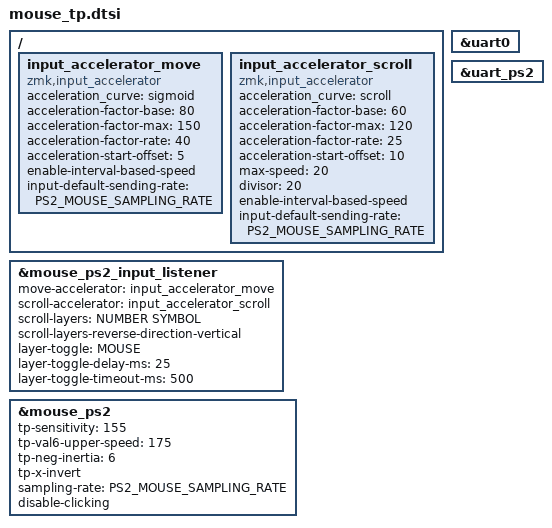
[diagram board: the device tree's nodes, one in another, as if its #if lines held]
#ifdef HAS_MOUSE_TP

#include <dt-bindings/zmk/mouse.h>
#include <dt-bindings/zmk/mouse_settings.h>
#include <behaviors/mouse_keys.dtsi>
#include <behaviors/mouse_setting.dtsi>
//#include <input/processors.dtsi>
//#include <dt-bindings/zmk/input_transform.h>
//#include <zephyr/dt-bindings/input/input-event-codes.h>

/*
* Key Behaviors to adjust settings
*/

// Sensitivity
#define U_MSS_TP_S_I &mms MS_TP_SENSITIVITY_INCR
#define U_MSS_TP_S_D &mms MS_TP_SENSITIVITY_DECR

// Max acceleration
#define U_MSS_TP_V6_I &mms MS_TP_VALUE6_INCR
#define U_MSS_TP_V6_D &mms MS_TP_VALUE6_DECR

// Negative intertia
#define U_MSS_TP_NI_I &mms MS_TP_NEG_INERTIA_INCR
#define U_MSS_TP_NI_D &mms MS_TP_NEG_INERTIA_DECR

#define U_MSS_RESET   &mms MS_RESET

#define U_MSS_LOG     &mms MS_LOG


#ifdef MOUSE_PS2_DT_PRESENT

#define PS2_MOUSE_SAMPLING_RATE 100

/*
* Input Listener Config
*/
/ {
    input_accelerator_move: input_accelerator_move {
        status = "okay";
        compatible = "zmk,input_accelerator";

        acceleration_curve = "sigmoid";
        acceleration-factor-base = <80>;
        acceleration-factor-max = <150>;
        acceleration-factor-rate = <40>;
        acceleration-start-offset = <5>;

        enable-interval-based-speed;
        input-default-sending-rate = <PS2_MOUSE_SAMPLING_RATE>;
    };
    input_accelerator_scroll: input_accelerator_scroll {
        status = "okay";
        compatible = "zmk,input_accelerator";

        acceleration_curve = "scroll";
        acceleration-factor-base = <60>;
        acceleration-factor-max = <120>;
        acceleration-factor-rate = <25>;
        acceleration-start-offset = <10>;
        max-speed = <20>;
        divisor = <20>;

        enable-interval-based-speed;
        input-default-sending-rate = <PS2_MOUSE_SAMPLING_RATE>;
    };
};

&mouse_ps2_input_listener { 
    move-accelerator = <&input_accelerator_move>;
    scroll-accelerator = <&input_accelerator_scroll>;

    scroll-layers = <NUMBER SYMBOL>; 
    scroll-layers-reverse-direction-vertical; 

    layer-toggle = <MOUSE>; 
    layer-toggle-delay-ms = <25>; 
    layer-toggle-timeout-ms = <500>; 
};

//&trackpoint_listener { 
//    input-processors = <&zip_temp_layer MOUSE 500>;
//};

/*
* Mouse Driver Settings
*/

&mouse_ps2 {
    // How sensitive the TP is (Default: 128)
    tp-sensitivity = <155>;
    // The maximum mouse movement speed the TP will accelarate to
    // (Default: 97)
    tp-val6-upper-speed = <175>;
    // Negative Inertia (Default: 6)
    // Makes the TP feel more responsive and "overshoot" less.
    tp-neg-inertia = <6>;

    tp-x-invert;

    sampling-rate = <PS2_MOUSE_SAMPLING_RATE>;

    disable-clicking;
};

// Enable PS/2 Mouse Devices
// In `your_keyboard_right.overlay` all devices have `status = "disabled"`.
// So,they are never compiled into the firmware.
//
// Here we enable them, but we do it within the #ifdef HAS_MOUSE_TP code
// block, which prevents compilation and potential build errors when we
// undefine HAS_MOUSE_TP in corne_tp.keymap
&mouse_ps2  {
    status = "okay";
};

&mouse_ps2_input_listener {
    status = "okay";
};
//&trackpoint_listener {
//    status = "okay";
//};

#ifdef MOUSE_PS2_DRIVER_UART

&uart0 {
    status = "okay";
};

&uart_ps2 {
    status="okay";
};

#else

&gpio_ps2  {
    status = "okay";
};

#endif  // MOUSE_PS2_DRIVER_UART

#endif  // MOUSE_PS2_DT_PRESENT

#endif  // HAS_MOUSE_TP
